VERSION ""

NS_ :

BS_:

BU_: ECU_06 ECU_05 ECU_04 Gateway ECU_03 ECU_02 ECU_01

BO_ 243 Butterfly_Valve_Pos: 1 ECU_01
 SG_ Butterfly_Valve_Pos : 0|1@1+ (1,0) [0|0] ""  Gateway

BO_ 162 Rear_Brake_Disk_Temp: 4 Vector__XXX
 SG_ L_Rear_Brake_Disk_Temp : 0|10@1- (0.12219,22.56128) [-40|85.00037] "degC"  Gateway
 SG_ R_Rear_Brake_Disk_Temp : 16|10@1- (0.12219,22.56128) [-40|85.00037] "degC"  Gateway

BO_ 227 TBI_Temp: 1 Vector__XXX
 SG_ TBI_Temp : 0|1@1- (1,0) [0|0] ""  Gateway

BO_ 211 TBI_MAP: 1 Vector__XXX
 SG_ TBI_MAP : 0|1@1- (1,0) [0|0] ""  Gateway

BO_ 195 TBI: 1 Vector__XXX
 SG_ TBI : 0|1@1- (1,0) [0|0] ""  Gateway

BO_ 179 Strain_Gauge: 1 Vector__XXX
 SG_ Strain_Gauge : 0|1@1- (1,0) [0|0] ""  Gateway

BO_ 163 TPMS: 1 Vector__XXX
 SG_ TPMS : 0|1@1- (1,0) [0|0] ""  Gateway

BO_ 242 Rear_Brake_Fluid_Pressure: 1 Vector__XXX
 SG_ Rear_Brake_Fluid_Pressure : 0|8@1+ (0.0392,0) [0|9.996] "Bar"  Gateway

BO_ 226 Front_Brake_Fluid_Pressure: 1 Vector__XXX
 SG_ Front_Brake_Fluid_Pressure : 0|8@1+ (0.0392,0) [0|9.996] "Bar"  Gateway

BO_ 194 Brake_Pedal_Pos: 1 ECU_01
 SG_ Brake_Pedal_Pos : 0|8@1+ (1,0) [0|255] "%"  Gateway

BO_ 178 Front_Brake_Disk_Temp: 4 Vector__XXX
 SG_ R_Front_Brake_Disk_Temp : 16|10@1- (0.12219,22.56128) [-40|85.00037] "degC"  Gateway
 SG_ L_Front_Brake_Disk_Temp : 0|10@1- (0.12219,22.56128) [-40|85.00037] "degC"  Gateway

BO_ 241 Balance_Bar: 1 Vector__XXX
 SG_ Balance_Bar : 0|1@1- (1,0) [0|0] ""  Gateway

BO_ 225 Fuel_Pressure: 1 Vector__XXX
 SG_ Fuel_Pressure : 0|8@1+ (0.0392,0) [0|9.996] "Bar"  Gateway

BO_ 209 Battery_Current: 1 ECU_02
 SG_ Battery_Current : 0|1@1- (1,0) [0|0] "A"  Gateway

BO_ 193 Battery_Voltage: 1 ECU_02
 SG_ Battery_Voltage : 0|1@1- (1,0) [0|0] "V"  Gateway

BO_ 514 Gear_Pos: 1 ECU_04
 SG_ Gear_Pos : 0|8@1+ (1,0) [0|6] "Gear"  Gateway

BO_ 769 Speed: 1 ECU_02
 SG_ Speed : 0|8@1+ (1,0) [0|255] "km/h"  Gateway

BO_ 257 Lambda_Sensor: 1 ECU_05
 SG_ Lambda_Sensor : 0|8@1+ (0.01,0) [0|2.55] ""  Gateway

BO_ 513 Air_Temp: 1 ECU_03
 SG_ Air_Temp : 0|8@1+ (1,0) [0|255] "degC"  Gateway

BO_ 258 MAP: 2 ECU_03
 SG_ MAP : 0|10@1+ (250,0) [0|255750] "Pa"  Gateway

BO_ 2 RPM: 2 ECU_05
 SG_ RPM_Sensor : 0|16@1+ (1,0) [0|13000] "RPM"  Gateway

BO_ 259 TPS: 1 ECU_03
 SG_ TPS : 0|8@1+ (1,0) [0|255] "%"  Gateway

BO_ 518 Water_Temp: 1 ECU_05
 SG_ Water_Temp : 0|8@1+ (1,0) [0|255] "degC"  Gateway

BO_ 1 Oil_Pressure: 1 ECU_05
 SG_ Oil_Pressure : 0|8@1+ (0.0392,0) [0|9.996] "Bar"  Gateway

BO_ 515 Oil_Temp: 1 ECU_05
 SG_ Oil_Temp : 0|8@1+ (1,0) [0|255] "degC"  Gateway

BO_ 161 Intercooler_Output_Pressure: 1 ECU_04
 SG_ Intercooler_Output_Pressure : 0|1@1- (1,0) [0|0] ""  Gateway

BO_ 15 Turbo_Intercooler_Pressure: 1 ECU_04
 SG_ Turbo_Intercooler_Pressure : 0|1@1- (1,0) [0|0] ""  Gateway

BO_ 14 Rest_Turbo_Pressure: 1 ECU_04
 SG_ Rest_Turbo_Pressure : 0|1@1- (1,0) [0|0] ""  Gateway

BO_ 13 Intercooler_Output_Temp: 1 ECU_04
 SG_ Intercooler_Output_Temp : 0|8@1+ (1,0) [0|255] "degC"  Gateway

BO_ 12 Turbo_Intercooler_Temp: 1 ECU_04
 SG_ Turbo_Intercooler_Temp : 0|8@1+ (1,0) [0|255] "degC"  Gateway

BO_ 11 Rest_Turbo_Temp: 1 ECU_05
 SG_ Rest_Turbo_Temp : 0|8@1+ (1,0) [0|255] "degC"  Gateway

BO_ 1029 Rear_Susp_Pos: 4 ECU_02
 SG_ R_Rear_Susp_Pos : 16|10@1+ (0.088,0) [0|90.024] "deg"  Gateway
 SG_ L_Rear_Susp_Pos : 0|10@1+ (0.088,0) [0|90.024] "deg"  Gateway

BO_ 1028 Front_Susp_Pos: 4 ECU_01
 SG_ R_Front_Susp_Pos : 16|10@1+ (0.088,0) [0|90.024] "deg"  Gateway
 SG_ L_Front_Susp_Pos : 0|10@1+ (0.088,0) [0|90.024] "deg"  Gateway

BO_ 10 Steering_Wheel_Pos: 2 ECU_03
 SG_ Steering_Wheel_Pos : 0|10@1- (1,0) [-512|511] "deg"  Gateway

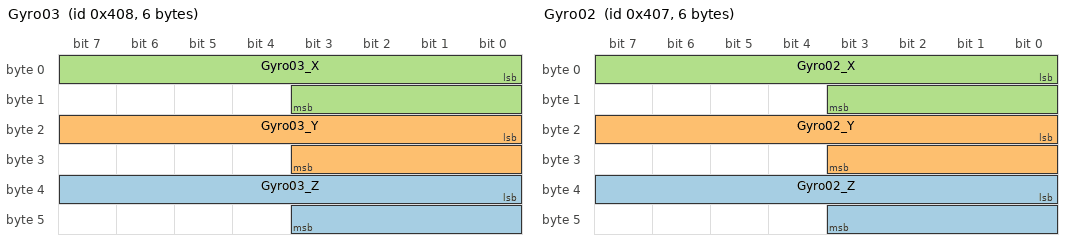
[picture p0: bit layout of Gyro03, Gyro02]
BO_ 1032 Gyro03: 6 ECU_02
 SG_ Gyro03_Z : 32|12@1- (0.125,0) [-256|255.875] "deg/s"  Gateway
 SG_ Gyro03_Y : 16|12@1- (0.125,0) [-256|255.875] "deg/s"  Gateway
 SG_ Gyro03_X : 0|12@1- (0.125,0) [-256|255.875] "deg/s"  Gateway

BO_ 1031 Gyro02: 6 ECU_02
 SG_ Gyro02_Z : 32|12@1- (0.125,0) [-256|255.875] "deg/s"  Gateway
 SG_ Gyro02_Y : 16|12@1- (0.125,0) [-256|255.875] "deg/s"  Gateway
 SG_ Gyro02_X : 0|12@1- (0.125,0) [-256|255.875] "deg/s"  Gateway

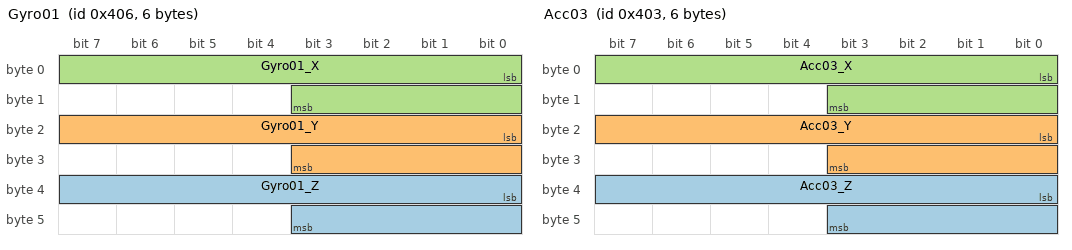
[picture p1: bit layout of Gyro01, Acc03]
BO_ 1030 Gyro01: 6 ECU_01
 SG_ Gyro01_Z : 32|12@1- (0.125,0) [-256|255.875] "deg/s"  Gateway
 SG_ Gyro01_Y : 16|12@1- (0.125,0) [-256|255.875] "deg/s"  Gateway
 SG_ Gyro01_X : 0|12@1- (0.125,0) [-256|255.875] "deg/s"  Gateway

BO_ 1027 Acc03: 6 ECU_02
 SG_ Acc03_Z : 32|12@1- (0.002,0) [-4.096|4.094] "G"  Gateway
 SG_ Acc03_Y : 16|12@1- (0.002,0) [-4.096|4.094] "G"  Gateway
 SG_ Acc03_X : 0|12@1- (0.002,0) [-4.096|4.094] "G"  Gateway

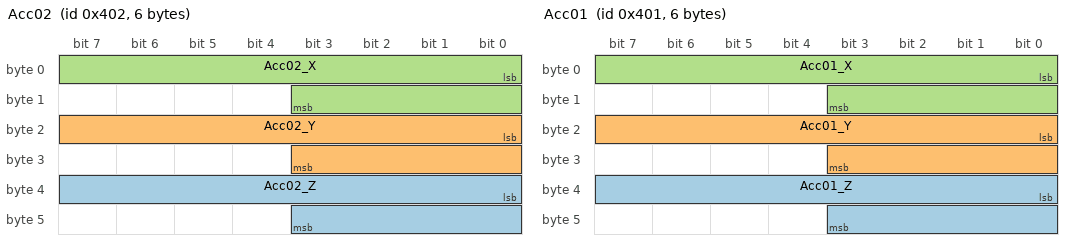
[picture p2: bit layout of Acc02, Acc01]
BO_ 1026 Acc02: 6 ECU_02
 SG_ Acc02_Z : 32|12@1- (0.002,0) [-4.096|4.094] "G"  Gateway
 SG_ Acc02_Y : 16|12@1- (0.002,0) [-4.096|4.094] "G"  Gateway
 SG_ Acc02_X : 0|12@1- (0.002,0) [-4.096|4.094] "G"  Gateway

BO_ 1025 Acc01: 6 ECU_01
 SG_ Acc01_Z : 32|12@1- (0.002,0) [-4.096|4.094] "G"  Gateway
 SG_ Acc01_Y : 16|12@1- (0.002,0) [-4.096|4.094] "G"  Gateway
 SG_ Acc01_X : 0|12@1- (0.002,0) [-4.096|4.094] "G"  Gateway

BA_DEF_  "BusType" STRING ;
BA_DEF_DEF_  "BusType" "CAN";
